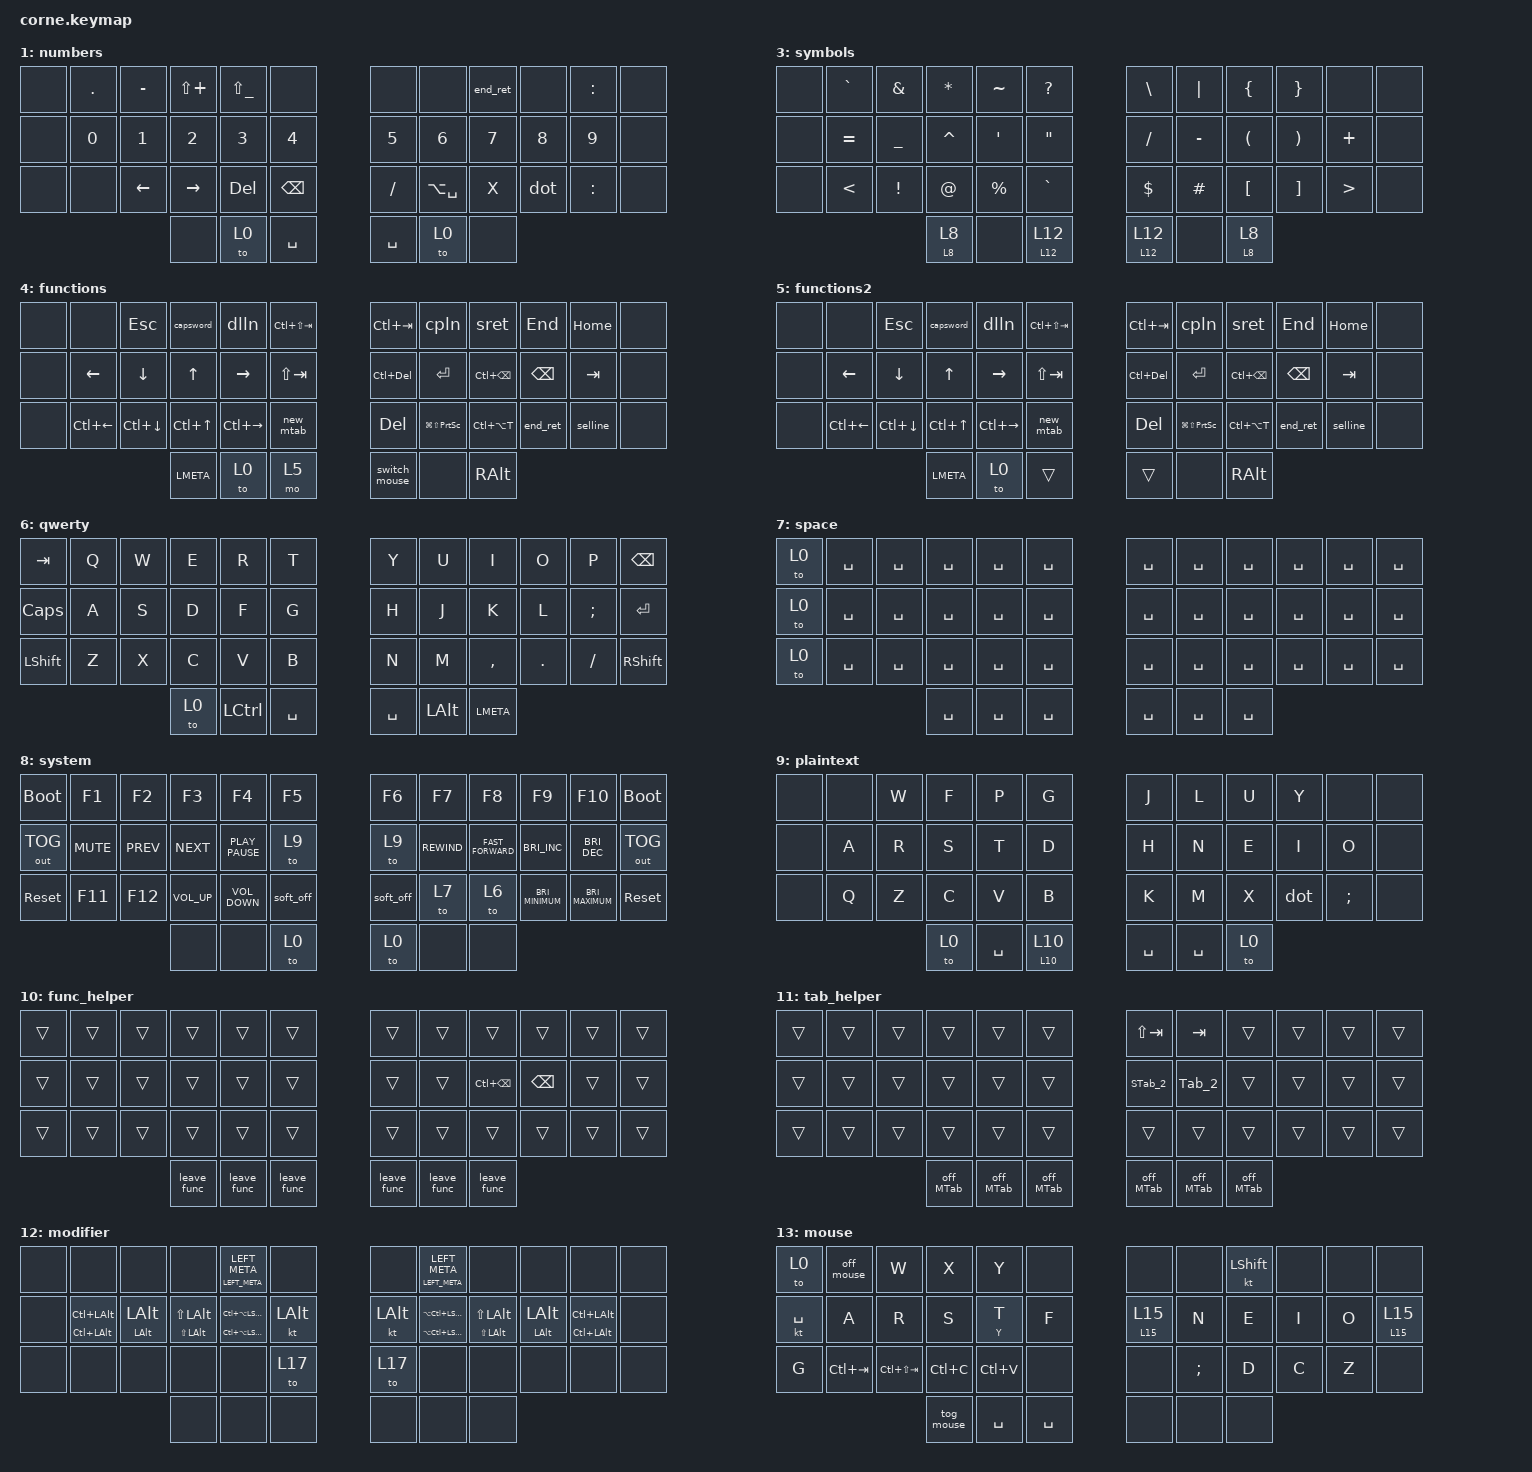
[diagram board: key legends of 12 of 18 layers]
/*
 * Copyright (c) 2020 The ZMK Contributors
 *
 * SPDX-License-Identifier: MIT
 */

#include <behaviors.dtsi>
#include <dt-bindings/zmk/bt.h>
#include <dt-bindings/zmk/keys.h>
#include <dt-bindings/zmk/outputs.h>

/ {
    behaviors {
        dot: dot {
            compatible = "zmk,behavior-tap-dance";
            label = "DOT";
            #binding-cells = <0>;
            bindings = <&kp PERIOD>, <&kp COMMA>;
        };

        ht_ctl: ht_ctl {
            compatible = "zmk,behavior-hold-tap";
            label = "HT_CTL";
            bindings = <&kp>, <&sk>;

            #binding-cells = <2>;
            tapping-term-ms = <500>;
        };

        nx_fn: nx_fn {
            compatible = "zmk,behavior-sticky-key";
            label = "NX_FN";
            bindings = <&to>;
            #binding-cells = <1>;
            release-after-ms = <500>;
        };

        ht_lyr: ht_lyr {
            compatible = "zmk,behavior-hold-tap";
            label = "HT_LYR";
            bindings = <&mo>, <&sl>;

            #binding-cells = <2>;
            tapping-term-ms = <160>;
            flavor = "balanced";
            quick-tap-ms = <100>;
        };

        ht_k: ht_k {
            compatible = "zmk,behavior-hold-tap";
            label = "HT_K";
            bindings = <&kp>, <&kp>;

            #binding-cells = <2>;
            tapping-term-ms = <150>;
            flavor = "balanced";
        };

        left_hrm: left_hrm {
            compatible = "zmk,behavior-hold-tap";
            label = "LEFT_HRM";
            #binding-cells = <2>;
            flavor = "balanced";
            tapping-term-ms = <140>;
            hold-trigger-key-positions = <6 7 8 9 10 11 18 19 20 21 22 23 30 31 32 33 34 35 39 40 41 36 37 38 0 12 24>;
            bindings = <&kp>, <&kp>;

            require-prior-idle-ms = <70>;
            hold-trigger-on-release;
        };

        right_hrm: right_hrm {
            compatible = "zmk,behavior-hold-tap";
            label = "RIGHT_HRM";
            bindings = <&kp>, <&kp>;

            #binding-cells = <2>;
            tapping-term-ms = <140>;
            flavor = "balanced";
            hold-trigger-key-positions = <0 1 2 3 4 5 12 13 14 15 16 17 24 25 26 27 28 29 36 37 38 39 40 41 11 23 35>;
            require-prior-idle-ms = <70>;
            hold-trigger-on-release;
        };

        left_hrm2: left_hrm2 {
            compatible = "zmk,behavior-hold-tap";
            label = "LEFT_HRM2";
            #binding-cells = <2>;
            flavor = "balanced";
            tapping-term-ms = <145>;
            hold-trigger-key-positions = <6 7 9 10 11 18 19 20 21 22 23 30 31 32 33 34 35 39 40 41 8 36 37 38 0 12 24>;
            bindings = <&mo>, <&kp>;

            require-prior-idle-ms = <75>;
            hold-trigger-on-release;
        };

        right_hrm2: right_hrm2 {
            compatible = "zmk,behavior-hold-tap";
            label = "RIGHT_HRM2";
            bindings = <&mo>, <&kp>;

            #binding-cells = <2>;
            tapping-term-ms = <145>;
            flavor = "balanced";
            hold-trigger-key-positions = <0 1 5 12 13 14 15 16 17 24 25 26 27 28 29 36 37 38 2 3 4 39 40 41 11 23 35>;
            require-prior-idle-ms = <75>;
            hold-trigger-on-release;
            quick-tap-ms = <0>;
        };

        mtab: mtab {
            compatible = "zmk,behavior-tap-dance";
            label = "MTAB";
            #binding-cells = <0>;
            bindings = <&on_MTab>, <&kp LG(TAB)>;

            tapping-term-ms = <150>;
        };

        ht_td_lyr: ht_td_lyr {
            compatible = "zmk,behavior-tap-dance";
            label = "HT_TD_LYR";
            #binding-cells = <0>;
            bindings = <&ht_lyr 1 4>, <&to 4>;

            tapping-term-ms = <180>;
        };

        ht_sk: ht_sk {
            compatible = "zmk,behavior-hold-tap";
            label = "HT_SK";
            bindings = <&kp>, <&sk>;

            #binding-cells = <2>;
            tapping-term-ms = <210>;
            flavor = "tap-preferred";
        };

        ht_to_func: ht_to_func {
            compatible = "zmk,behavior-hold-tap";
            label = "HT_TO_FUNC";
            bindings = <&to_mo_func>, <&toFunc>;

            #binding-cells = <2>;
            tapping-term-ms = <200>;
        };

        hrm4: hrm4 {
            compatible = "zmk,behavior-hold-tap";
            label = "HRM4";
            bindings = <&kp>, <&kp>;

            #binding-cells = <2>;
            flavor = "tap-preferred";
            tapping-term-ms = <200>;
        };

        left_hrm_3: left_hrm_3 {
            compatible = "zmk,behavior-hold-tap";
            label = "LEFT_HRM_3";
            #binding-cells = <2>;
            flavor = "tap-preferred";
            tapping-term-ms = <185>;
            hold-trigger-key-positions = <6 7 8 9 10 11 18 19 20 21 22 23 30 31 32 33 34 35 39 40 41 36 37 38 0 12 24>;
            bindings = <&kp>, <&kp>;

            require-prior-idle-ms = <75>;
            hold-trigger-on-release;
        };

        right_hrm_3: right_hrm_3 {
            compatible = "zmk,behavior-hold-tap";
            label = "RIGHT_HRM_3";
            bindings = <&kp>, <&kp>;

            #binding-cells = <2>;
            tapping-term-ms = <185>;
            flavor = "tap-preferred";
            hold-trigger-key-positions = <0 1 2 3 4 5 12 13 14 15 16 17 24 25 26 27 28 29 36 37 38 39 40 41 11 23 35>;
            require-prior-idle-ms = <75>;
            hold-trigger-on-release;
        };

        morph_caps_word: morph_caps_word {
            compatible = "zmk,behavior-mod-morph";
            label = "MORPH_CAPS_WORD";
            bindings = <&capsword>, <&caps_word>;

            #binding-cells = <0>;
            mods = <(MOD_LSFT|MOD_RSFT)>;
        };

        caps_word1: caps_word1 {
            compatible = "zmk,behavior-caps-word";
            label = "CAPS_WORD1";
            #binding-cells = <0>;
            continue-list = <F22>;
            mods = <(MOD_LSFT)>;
        };

        speed0_5: speed0_5 {
            compatible = "zmk,behavior-tap-dance";
            label = "SPEED0_5";
            #binding-cells = <0>;
            bindings = <&kp W>, <&kt W>;

            tapping-term-ms = <130>;
        };

        speed3: speed3 {
            compatible = "zmk,behavior-tap-dance";
            label = "SPEED3";
            #binding-cells = <0>;
            bindings = <&kp X>, <&kt X>;

            tapping-term-ms = <130>;
        };

        speed2: speed2 {
            compatible = "zmk,behavior-tap-dance";
            label = "SPEED2";
            #binding-cells = <0>;
            bindings = <&kp Y>, <&kt Y>;

            tapping-term-ms = <130>;
        };

        mtab_hold: mtab_hold {
            compatible = "zmk,behavior-hold-tap";
            label = "MTAB_HOLD";
            bindings = <&new_mtab>, <&kp>;

            #binding-cells = <2>;
            tapping-term-ms = <200>;
        };
    };

    macros {
        sret: sret {
            compatible = "zmk,behavior-macro";
            #binding-cells = <0>;
            bindings = <&kp END &kp LS(RET)>;
            label = "SRET";
        };

        af4: af4 {
            compatible = "zmk,behavior-macro";
            #binding-cells = <0>;
            bindings = <&kt LEFT_ALT &kp F4 &kt LEFT_ALT>;
            label = "AF4";
        };

        end_ret: endRet {
            compatible = "zmk,behavior-macro";
            #binding-cells = <0>;
            bindings = <&kp END &kp RET>;
            label = "ENDRET";
        };

        cpln: cpln {
            compatible = "zmk,behavior-macro";
            #binding-cells = <0>;
            bindings = <&kp HOME &kp HOME &kp HOME &kp LS(END) &kp LS(END) &kp LS(END) &kp LC(C) &kp END>;
            label = "CPLN";
        };

        dlln: dlln {
            compatible = "zmk,behavior-macro";
            #binding-cells = <0>;
            bindings = <&kp HOME &kp HOME &kp LS(END) &kp LS(END) &kp DEL>;
            label = "DLLN";
        };

        sw1: sw1 {
            compatible = "zmk,behavior-macro";
            #binding-cells = <0>;
            bindings = <&kp LS(LG(LEFT_ARROW)) &kp LG(LA(H)) &kp LS(LG(RIGHT))>;
            label = "SW1";
        };

        sw2: sw2 {
            compatible = "zmk,behavior-macro";
            #binding-cells = <0>;
            bindings = <&kp LS(LG(RIGHT)) &kp LA(LG(H)) &kp LS(LG(LEFT_ARROW))>;
            label = "SW2";
        };

        capsword: capsword {
            compatible = "zmk,behavior-macro";
            #binding-cells = <0>;
            bindings = <&kp F22 &caps_word1>;
            label = "CAPSWORD";
        };

        toFunc: toFunc {
            compatible = "zmk,behavior-macro";
            #binding-cells = <0>;
            bindings = <&kp F22 &to 4 &tog 10>;
            label = "TOFUNC";
        };

        leave_func: leave_func {
            compatible = "zmk,behavior-macro";
            #binding-cells = <0>;
            bindings = <&tog 10 &to 0>;
            label = "LEAVE_FUNC";
        };

        on_MTab: on_MTab {
            compatible = "zmk,behavior-macro";
            #binding-cells = <0>;
            bindings = <&kt LEFT_META &tog 11 &kp TAB>;
            label = "ON_MTAB";
        };

        on_MSTab: on_MSTab {
            compatible = "zmk,behavior-macro";
            #binding-cells = <0>;
            bindings = <&kt LEFT_META &tog 11 &kp LS(TAB)>;
            label = "ON_MSTAB";
        };

        off_MTab: off_MTab {
            compatible = "zmk,behavior-macro";
            #binding-cells = <0>;
            bindings = <&kt LEFT_META &tog 11>;
            label = "OFF_MTAB";
        };

        STab_2: STab_2 {
            compatible = "zmk,behavior-macro";
            #binding-cells = <0>;
            bindings = <&kp LS(TAB) &kp LS(TAB)>;
            label = "STAB_2";
        };

        Tab_2: Tab_2 {
            compatible = "zmk,behavior-macro";
            #binding-cells = <0>;
            bindings = <&kp TAB &kp TAB>;
            label = "TAB_2";
        };

        selline: selline {
            compatible = "zmk,behavior-macro";
            #binding-cells = <0>;
            bindings = <&kp HOME &kp HOME &kp LS(END) &kp LS(END)>;
            label = "SELLINE";
        };

        to_OH_2: to_OH_2 {
            compatible = "zmk,behavior-macro";
            #binding-cells = <0>;
            bindings = <&kp F22 &to 0 &tog 0>;
            label = "TO_OH_2";
        };

        leave_OH_2: leave_OH_2 {
            compatible = "zmk,behavior-macro";
            #binding-cells = <0>;
            bindings = <&to 0 &tog 0>;
            label = "LEAVE_OH_2";
        };

        to_mo_func: to_mo_func {
            compatible = "zmk,behavior-macro";
            #binding-cells = <0>;
            bindings = <&kp F22 &mo 4>;
            label = "TO_MO_FUNC";
        };

        dlln2: dlln2 {
            compatible = "zmk,behavior-macro";
            #binding-cells = <0>;
            bindings = <&kp END &kp END &kp LS(LC(BACKSPACE))>;
            label = "DLLN2";
        };

        cut_line: cut_line {
            compatible = "zmk,behavior-macro";
            #binding-cells = <0>;
            bindings = <&kp HOME &kp HOME &kp LS(END) &kp LS(END) &kp LC(X)>;
            label = "CUT_LINE";
        };

        switch_mouse: switch_mouse {
            compatible = "zmk,behavior-macro";
            #binding-cells = <0>;
            bindings =
                <&macro_press>,
                <&mo 13 &kp SCROLLLOCK>,
                <&macro_pause_for_release>,
                <&macro_release>,
                <&mo 13 &kp SCROLLLOCK>;

            label = "SWITCH_MOUSE";
        };

        off_mouse: off_mouse {
            compatible = "zmk,behavior-macro";
            #binding-cells = <0>;
            bindings = <&kp Q &to 0>;
            label = "OFF_MOUSE";
        };

        tog_mouse: tog_mouse {
            compatible = "zmk,behavior-macro";
            #binding-cells = <0>;
            bindings = <&kp LEFT_ALT &to 14>;
            label = "TOG_MOUSE";
        };

        left_mousemove: left_mousemove {
            compatible = "zmk,behavior-macro";
            #binding-cells = <0>;
            bindings = <&kp LS(LG(LC(J))) &kp LG(F5)>;
            label = "LEFT_MOUSEMOVE";
        };

        right_mousemove: right_mousemove {
            compatible = "zmk,behavior-macro";
            #binding-cells = <0>;
            bindings = <&kp LS(LG(LC(H))) &kp LG(F5)>;
            label = "RIGHT_MOUSEMOVE";
        };

        mousemove: mousemove {
            compatible = "zmk,behavior-macro";
            #binding-cells = <0>;
            bindings = <&kp LG(LA(F)) &kp LG(F5)>;
            label = "MOUSEMOVE";
        };

        new_mtab: new_mtab {
            compatible = "zmk,behavior-macro";
            #binding-cells = <0>;
            bindings =
                <&macro_press>,
                <&mo 16 &kp LEFT_META>,
                <&macro_tap>,
                <&kp TAB>,
                <&macro_pause_for_release>,
                <&macro_release>,
                <&mo 16 &kp LEFT_GUI>;

            label = "NEW_MTAB";
        };
    };

    combos {
        compatible = "zmk,combos";

        cut {
            bindings = <&cut_line>;
            key-positions = <4 7>;
            layers = <4 5>;
        };
    };

    keymap {
        compatible = "zmk,keymap";

        default_layer {
            // -----------------------------------------------------------------------------------------
            // |  TAB |  Q  |  W  |  E  |  R  |  T  |   |  Y  |  U   |  I  |  O  |  P  | BSPC |
            // | CTRL |  A  |  S  |  D  |  F  |  G  |   |  H  |  J   |  K  |  L  |  ;  |  '   |
            // | SHFT |  Z  |  X  |  C  |  V  |  B  |   |  N  |  M   |  ,  |  .  |  /  | ESC  |
            //                    | GUI | LWR | SPC |   | ENT | RSE  | ALT |

            bindings = <
&kp LS(LC(LG(D)))  &ht_lyr 8 8  &kp W           &kp F                &kp P              &kp G          &kp J        &kp L               &kp U                 &kp Y            &ht_lyr 8 8    &kp RCTRL
&kp RALT           &kp A        &left_hrm2 3 R  &left_hrm_3 LCTRL S  &left_hrm LSHFT T  &kp D          &kp H        &right_hrm LSHFT N  &right_hrm_3 LCTRL E  &right_hrm2 3 I  &kp O          &kp RALT
&kp LEFT_GUI       &kp Q        &kp Z           &kp C                &kp V              &kp B          &kp K        &kp M               &kp X                 &dot             &kp SEMICOLON  &kp LEFT_GUI
                                                &ht_lyr 12 12        &lt 2 SPACE        &ht_lyr 1 4    &ht_lyr 1 4  &lt 2 SPACE         &ht_lyr 12 12
            >;
        };

        numbers {
            // -----------------------------------------------------------------------------------------
            // |  TAB |  1  |  2  |  3  |  4  |  5  |   |  6  |  7  |  8  |  9  |  0  | BSPC |
            // | BTCLR| BT1 | BT2 | BT3 | BT4 | BT5 |   | LFT | DWN |  UP | RGT |     |      |
            // | SHFT |     |     |     |     |     |   |     |     |     |     |     |      |
            //                    | GUI |     | SPC |   | ENT |     | ALT |

            bindings = <
&none  &kp DOT  &kp MINUS       &kp LS(PLUS)  &kp LS(UNDER)  &none            &none      &none          &end_ret  &none   &kp COLON  &none
&none  &kp N0   &kp N1          &kp N2        &kp N3         &kp N4           &kp N5     &kp N6         &kp N7    &kp N8  &kp N9     &none
&none  &none    &kp LEFT_ARROW  &kp RIGHT     &kp DELETE     &kp BACKSPACE    &kp FSLH   &kp LA(SPACE)  &kp X     &dot    &kp COLON  &none
                                &none         &to 0          &kp SPACE        &kp SPACE  &to 0          &none
            >;
        };

        navigation {
            bindings = <
&none  &none               &kp LG(LC(LS(T)))  &kp LG(LC(LS(Q)))   &kp LG(RET)    &af4                 &on_MSTab             &mtab_hold 0 LG(TAB)  &kp LG(H)                    &kp LG(F)               &none              &none
&none  &kp LG(LC(LS(J)))   &kp LS(LC(LG(H)))  &kp LG(LA(J))       &kp LA(LG(H))  &kp LG(LC(LS(R)))    &kp LG(LC(UP_ARROW))  &kp LS(LC(LG(Z)))     &kp LG(LC(RIGHT))            &kp LG(LS(LEFT_ARROW))  &kp LS(LG(RIGHT))  &none
&none  &kp LG(DOWN_ARROW)  &kp LG(UP_ARROW)   &kp LG(LEFT_ARROW)  &kp LG(RIGHT)  &kp LG(F5)           &kp LG(F6)            &kp LC(LG(LS(UP)))    &kp LC(LG(LS(RIGHT_ARROW)))  &kp LC(END)             &kp LC(HOME)       &none
                                              &none               &none          &none                &none                 &none                 &none
            >;
        };

        symbols {
            bindings = <
&none  &kp GRAVE      &kp AMPERSAND    &kp ASTRK    &kp TILDE       &kp QUESTION         &kp BSLH       &kp PIPE   &kp LEFT_BRACE        &kp RIGHT_BRACE        &none             &none
&none  &kp EQUAL      &kp UNDER        &kp CARET    &kp APOSTROPHE  &kp DOUBLE_QUOTES    &kp SLASH      &kp MINUS  &kp LEFT_PARENTHESIS  &kp RIGHT_PARENTHESIS  &kp PLUS          &none
&none  &kp LESS_THAN  &kp EXCLAMATION  &kp AT       &kp PERCENT     &kp GRAVE            &kp DOLLAR     &kp HASH   &kp LBKT              &kp RBKT               &kp GREATER_THAN  &none
                                       &ht_lyr 8 8  &none           &ht_lyr 12 12        &ht_lyr 12 12  &none      &ht_lyr 8 8
            >;
        };

        functions {
            bindings = <
&none  &none         &kp ESC         &capsword     &dlln          &kp LC(LS(TAB))    &kp LC(TAB)     &cpln                    &sret          &kp END   &kp HOME  &none
&none  &kp LEFT      &kp DOWN_ARROW  &kp UP_ARROW  &kp RIGHT      &kp LS(TAB)        &kp LC(DELETE)  &kp RET                  &kp LC(BSPC)   &kp BSPC  &kp TAB   &none
&none  &kp LC(LEFT)  &kp LC(DOWN)    &kp LC(UP)    &kp LC(RIGHT)  &new_mtab          &kp DELETE      &kp LG(LS(PRINTSCREEN))  &kp LC(LA(T))  &end_ret  &selline  &none
                                     &kp LMETA     &to 0          &mo 5              &switch_mouse   &none                    &kp RALT
            >;
        };

        functions2 {
            bindings = <
&none  &none         &kp ESC         &capsword     &dlln          &kp LC(LS(TAB))    &kp LC(TAB)  &cpln                    &sret          &kp END   &kp HOME  &none
&none  &kp LEFT      &kp DOWN_ARROW  &kp UP_ARROW  &kp RIGHT      &kp LS(TAB)        &kp LC(DEL)  &kp RET                  &kp LC(BSPC)   &kp BSPC  &kp TAB   &none
&none  &kp LC(LEFT)  &kp LC(DOWN)    &kp LC(UP)    &kp LC(RIGHT)  &new_mtab          &kp DELETE   &kp LG(LS(PRINTSCREEN))  &kp LC(LA(T))  &end_ret  &selline  &none
                                     &kp LMETA     &to 0          &trans             &trans       &none                    &kp RALT
            >;
        };

        qwerty {
            bindings = <
&kp TAB    &kp Q  &kp W  &kp E  &kp R      &kp T        &kp Y      &kp U     &kp I      &kp O    &kp P     &kp BSPC
&kp CAPS   &kp A  &kp S  &kp D  &kp F      &kp G        &kp H      &kp J     &kp K      &kp L    &kp SEMI  &kp ENTER
&kp LSHFT  &kp Z  &kp X  &kp C  &kp V      &kp B        &kp N      &kp M     &kp COMMA  &kp DOT  &kp FSLH  &kp RSHFT
                         &to 0  &kp LCTRL  &kp SPACE    &kp SPACE  &kp LALT  &kp LMETA
            >;
        };

        space {
            bindings = <
&to 0  &kp SPACE  &kp SPACE  &kp SPACE  &kp SPACE  &kp SPACE    &kp SPACE  &kp SPACE  &kp SPACE  &kp SPACE  &kp SPACE  &kp SPACE
&to 0  &kp SPACE  &kp SPACE  &kp SPACE  &kp SPACE  &kp SPACE    &kp SPACE  &kp SPACE  &kp SPACE  &kp SPACE  &kp SPACE  &kp SPACE
&to 0  &kp SPACE  &kp SPACE  &kp SPACE  &kp SPACE  &kp SPACE    &kp SPACE  &kp SPACE  &kp SPACE  &kp SPACE  &kp SPACE  &kp SPACE
                             &kp SPACE  &kp SPACE  &kp SPACE    &kp SPACE  &kp SPACE  &kp SPACE
            >;
        };

        system {
            bindings = <
&bootloader   &kp F1      &kp F2      &kp F3           &kp F4             &kp F5       &kp F6     &kp F7        &kp F8              &kp F9                    &kp F10                   &bootloader
&out OUT_TOG  &kp K_MUTE  &kp K_PREV  &kp K_NEXT       &kp K_PLAY_PAUSE   &to 9        &to 9      &kp C_REWIND  &kp C_FAST_FORWARD  &kp C_BRI_INC             &kp C_BRI_DEC             &out OUT_TOG
&sys_reset    &kp F11     &kp F12     &kp C_VOLUME_UP  &kp C_VOLUME_DOWN  &soft_off    &soft_off  &to 7         &to 6               &kp C_BRIGHTNESS_MINIMUM  &kp C_BRIGHTNESS_MAXIMUM  &sys_reset
                                      &none            &none              &to 0        &to 0      &none         &none
            >;
        };

        plaintext {
            bindings = <
&none  &none  &kp W  &kp F  &kp P      &kp G            &kp J      &kp L      &kp U  &kp Y  &none          &none
&none  &kp A  &kp R  &kp S  &kp T      &kp D            &kp H      &kp N      &kp E  &kp I  &kp O          &none
&none  &kp Q  &kp Z  &kp C  &kp V      &kp B            &kp K      &kp M      &kp X  &dot   &kp SEMICOLON  &none
                     &to 0  &kp SPACE  &ht_lyr 10 10    &kp SPACE  &kp SPACE  &to 0
            >;
        };

        func_helper {
            bindings = <
&trans  &trans  &trans  &trans       &trans       &trans         &trans       &trans       &trans             &trans         &trans  &trans
&trans  &trans  &trans  &trans       &trans       &trans         &trans       &trans       &kp LC(BACKSPACE)  &kp BACKSPACE  &trans  &trans
&trans  &trans  &trans  &trans       &trans       &trans         &trans       &trans       &trans             &trans         &trans  &trans
                        &leave_func  &leave_func  &leave_func    &leave_func  &leave_func  &leave_func
            >;
        };

        tab_helper {
            bindings = <
&trans  &trans  &trans  &trans     &trans     &trans       &kp LS(TAB)  &kp TAB    &trans     &trans  &trans  &trans
&trans  &trans  &trans  &trans     &trans     &trans       &STab_2      &Tab_2     &trans     &trans  &trans  &trans
&trans  &trans  &trans  &trans     &trans     &trans       &trans       &trans     &trans     &trans  &trans  &trans
                        &off_MTab  &off_MTab  &off_MTab    &off_MTab    &off_MTab  &off_MTab
            >;
        };

        modifier {
            bindings = <
&none  &none                             &none             &none                             &ht_sk LEFT_META LEFT_META          &none           &none         &ht_sk LEFT_META LEFT_META           &none                             &none                 &none                             &none
&none  &ht_sk LC(LEFT_ALT) LC(LEFT_ALT)  &ht_sk LALT LALT  &ht_sk LS(LEFT_ALT) LS(LEFT_ALT)  &ht_sk LC(LA(LSHFT)) LC(LA(LSHFT))  &kt LEFT_ALT    &kt LEFT_ALT  &ht_sk LA(LC(LSHFT)) LA(LC(LSHIFT))  &ht_sk LS(LEFT_ALT) LS(LEFT_ALT)  &ht_sk LEFT_ALT LALT  &ht_sk LC(LEFT_ALT) LC(LEFT_ALT)  &none
&none  &none                             &none             &none                             &none                               &to 17          &to 17        &none                                &none                             &none                 &none                             &none
                                                           &none                             &none                               &none           &none         &none                                &none
            >;
        };

        mouse {
            bindings = <
&to 0      &off_mouse   &kp W            &kp X       &kp Y      &none        &none          &none          &kt LSHFT  &none  &none  &none
&kt SPACE  &kp A        &kp R            &kp S       &mt Y T    &kp F        &ht_lyr 15 15  &kp N          &kp E      &kp I  &kp O  &ht_lyr 15 15
&kp G      &kp LC(TAB)  &kp LC(LS(TAB))  &kp LC(C)   &kp LC(V)  &none        &none          &kp SEMICOLON  &kp D      &kp C  &kp Z  &none
                                         &tog_mouse  &kp SPACE  &kp SPACE    &none          &none          &none
            >;
        };

        mouse_locked {
            bindings = <
&to 0      &off_mouse   &kp W            &kp X       &kp Y      &none        &none          &none          &kt LSHFT  &none  &none  &none
&kt SPACE  &kp A        &kp R            &kp S       &mt Y T    &kp F        &ht_lyr 15 15  &kp N          &kp E      &kp I  &kp O  &ht_lyr 15 15
&kp G      &kp LC(TAB)  &kp LC(LS(TAB))  &kp LC(C)   &kp LC(V)  &none        &none          &kp SEMICOLON  &kp D      &kp C  &kp Z  &none
                                         &off_mouse  &kp SPACE  &kp SPACE    &none          &none          &none
            >;
        };

        mouse_funcs {
            bindings = <
&trans  &trans           &trans            &kp LG(F6)  &trans      &trans    &trans    &kp LALT       &kp LSHFT  &kp LCTRL  &trans  &trans
&trans  &left_mousemove  &right_mousemove  &kp LG(F5)  &mousemove  &trans    &trans    &trans         &trans     &trans     &trans  &trans
&trans  &kp LC(TAB)      &kp LS(LC(TAB))   &kp LC(C)   &kp LC(V)   &trans    &trans    &trans         &trans     &trans     &trans  &trans
                                           &kt Y       &kt W       &kt X     &kt LGUI  &kt LG(LCTRL)  &kt LGUI
            >;
        };

        tab_helper_2 {
            bindings = <
&trans  &trans  &trans  &trans  &trans  &trans    &trans   &trans       &trans  &trans  &trans  &trans
&trans  &trans  &trans  &trans  &trans  &trans    &trans   &trans       &trans  &trans  &trans  &trans
&trans  &trans  &trans  &trans  &trans  &trans    &trans   &trans       &trans  &trans  &trans  &trans
                        &trans  &trans  &trans    &kp TAB  &kp LS(TAB)  &trans
            >;
        };

        bluetooth {
            bindings = <
&none  &bt BT_CLR     &bt BT_CLR_ALL  &none          &none  &none    &none  &none  &none  &none  &none  &none
&none  &bt BT_SEL 0   &bt BT_SEL 1    &bt BT_SEL 2   &none  &none    &none  &none  &none  &none  &none  &none
&none  &bt BT_DISC 0  &bt BT_DISC 1   &bt BT_DISC 2  &none  &none    &none  &none  &none  &none  &none  &none
                                      &none          &none  &to 0    &to 0  &none  &none
            >;
        };
    };
};
